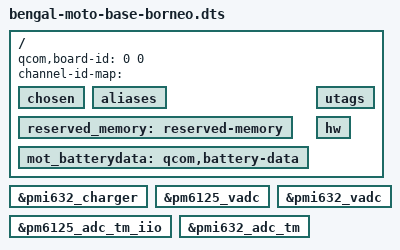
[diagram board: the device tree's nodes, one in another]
/* Copyright (c) 2020, The Linux Foundation. All rights reserved.
 *
 * This program is free software; you can redistribute it and/or modify
 * it under the terms of the GNU General Public License version 2 and
 * only version 2 as published by the Free Software Foundation.
 *
 * This program is distributed in the hope that it will be useful,
 * but WITHOUT ANY WARRANTY; without even the implied warranty of
 * MERCHANTABILITY or FITNESS FOR A PARTICULAR PURPOSE.  See the
 * GNU General Public License for more details.
 */

/dts-v1/;

#include "bengal-moto-base.dtsi"

/ {
	qcom,board-id = <0 0>;
	channel-id-map = "";
/*
 * Some nodes need labels assigned to appear in __symbols__
 */
	chosen: chosen { };
	aliases: aliases { };
	reserved_memory: reserved-memory { };
	mot_batterydata: qcom,battery-data { };
	utags: utags { };
	hw: hw { };
};

&pmi632_charger {
        /delete-property/ qcom,sw-jeita-enable;
        /delete-property/ qcom,step-charging-enable;
        /delete-property/ qcom,hw-die-temp-mitigation;
        /delete-property/ qcom,hw-connector-mitigation;
};

&pm6125_vadc {
	/delete-node/ emmc_ufs_therm;
};

&pm6125_adc_tm_iio {
	/delete-node/ emmc_ufs_therm;
};

&pmi632_vadc {
	/delete-node/ conn_therm;
	/delete-node/ skin_therm;
};

&pmi632_adc_tm {
	/delete-node/ skin_therm;
};
